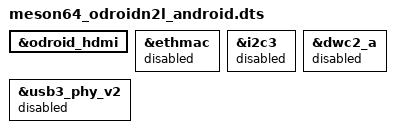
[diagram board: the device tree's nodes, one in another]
/*
 * arch/arm64/boot/dts/amlogic/meson64_odroidn2l_android.dts
 *
 * Copyright (C) 2018 Hardkernel Co., Ltd. All rights reserved.
 *
 * This program is free software; you can redistribute it and/or modify
 * it under the terms of the GNU General Public License as published by
 * the Free Software Foundation; either version 2 of the License, or
 * (at your option) any later version.
 *
 * This program is distributed in the hope that it will be useful, but WITHOUT
 * ANY WARRANTY; without even the implied warranty of MERCHANTABILITY or
 * FITNESS FOR A PARTICULAR PURPOSE.  See the GNU General Public License for
 * more details.
 *
 */

#include "meson64_odroidn2_android.dts"

/ {
	/delete-node/ gpio-reset;
};

&odroid_hdmi {
	/delete-property/ mute_gpio;
};

&ethmac {
	status = "disabled";
};

&i2c3 {
	status = "disabled";
	/delete-node/ rtc@51;
};

&usb3_phy_v2 {
	status = "disabled";
};

&dwc2_a {
	status = "disabled";
};
